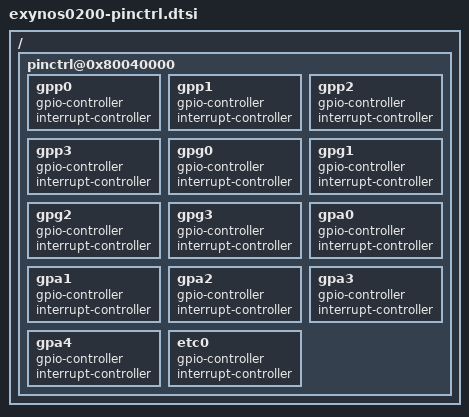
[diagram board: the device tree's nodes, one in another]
/*
 * Samsung's Exynos T20 SoC device tree source
 *
 * Copyright (c) 2016 Samsung Electronics Co., Ltd.
 *		http://www.samsung.com
 *
 * Samsung's Exynos T20 SoC device nodes are listed in this file.
 * Exynos T20 based board files can include this file and provide values
 * for board specfic bindings.
 *
 * Note: This file does not include device nodes for all the controllers
 * in Exynos T20 SoC. As device tree coverage for Exynos T20 increases,
 * additional nodes can be added to this file.
 *
 * This program is free software; you can redistribute it and/or modify
 * it under the terms of the GNU General Public License version 2 as
 * published by the Free Software Foundation.
 */

/ {
	pinctrl@0x80040000 {
		gpp0: gpp0 {
			gpio-controller;
			#gpio-cells = <2>;

			interrupt-controller;
			#interrupt-cells = <2>;
		};

		gpp1: gpp1 {
			gpio-controller;
			#gpio-cells = <2>;

			interrupt-controller;
			#interrupt-cells = <2>;
		};

		gpp2: gpp2 {
			gpio-controller;
			#gpio-cells = <2>;

			interrupt-controller;
			#interrupt-cells = <2>;
		};

		gpp3: gpp3 {
			gpio-controller;
			#gpio-cells = <2>;

			interrupt-controller;
			#interrupt-cells = <2>;
		};

		gpg0: gpg0 {
			gpio-controller;
			#gpio-cells = <2>;

			interrupt-controller;
			#interrupt-cells = <2>;
		};

		gpg1: gpg1 {
			gpio-controller;
			#gpio-cells = <2>;

			interrupt-controller;
			#interrupt-cells = <2>;
		};

		gpg2: gpg2 {
			gpio-controller;
			#gpio-cells = <2>;

			interrupt-controller;
			#interrupt-cells = <2>;
		};

		gpg3: gpg3 {
			gpio-controller;
			#gpio-cells = <2>;

			interrupt-controller;
			#interrupt-cells = <2>;
		};

		gpa0: gpa0 {
			gpio-controller;
			#gpio-cells = <2>;

			interrupt-controller;
			#interrupt-cells = <2>;
		};

		gpa1: gpa1 {
			gpio-controller;
			#gpio-cells = <2>;

			interrupt-controller;
			#interrupt-cells = <2>;
		};

		gpa2: gpa2 {
			gpio-controller;
			#gpio-cells = <2>;

			interrupt-controller;
			#interrupt-cells = <2>;
		};

		gpa3: gpa3 {
			gpio-controller;
			#gpio-cells = <2>;

			interrupt-controller;
			#interrupt-cells = <2>;
		};

		gpa4: gpa4 {
			gpio-controller;
			#gpio-cells = <2>;

			interrupt-controller;
			#interrupt-cells = <2>;
		};

		etc0: etc0 {
			gpio-controller;
			#gpio-cells = <2>;

			interrupt-controller;
			#interrupt-cells = <2>;
		};
	};
};
